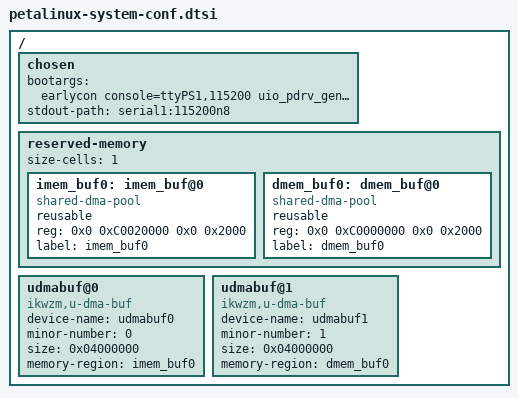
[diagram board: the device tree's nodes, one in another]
/include/ "system-conf.dtsi"
/ {
        chosen {
                bootargs = "earlycon console=ttyPS1,115200 uio_pdrv_genirq.of_id=generic-uio clk_ignore_unused init_fatal_sh=1 cma=900M ";
                stdout-path = "serial1:115200n8";
        };

    reserved-memory {
        #address-cells = <1>;
        #  size-cells = <1>;
        ranges;

        imem_buf0: imem_buf@0 {
            compatible = "shared-dma-pool";
            reusable;
            reg = <0x0 0xC0020000 0x0 0x2000>;
            label = "imem_buf0";
        };

        dmem_buf0: dmem_buf@0 {
            compatible = "shared-dma-pool";
            reusable;
            reg = <0x0 0xC0000000 0x0 0x2000>;
            label = "dmem_buf0";
        };
    };

    udmabuf@0 {
        compatible = "ikwzm,u-dma-buf";
        device-name = "udmabuf0";
        minor-number = <0>;
        size = <0x04000000>; // 64MiB
        memory-region = <&imem_buf0>;
    };
    udmabuf@1 {
        compatible = "ikwzm,u-dma-buf";
        device-name = "udmabuf1";
        minor-number = <1>;
        size = <0x04000000>; // 64MiB
        memory-region = <&dmem_buf0>;
    };
};

